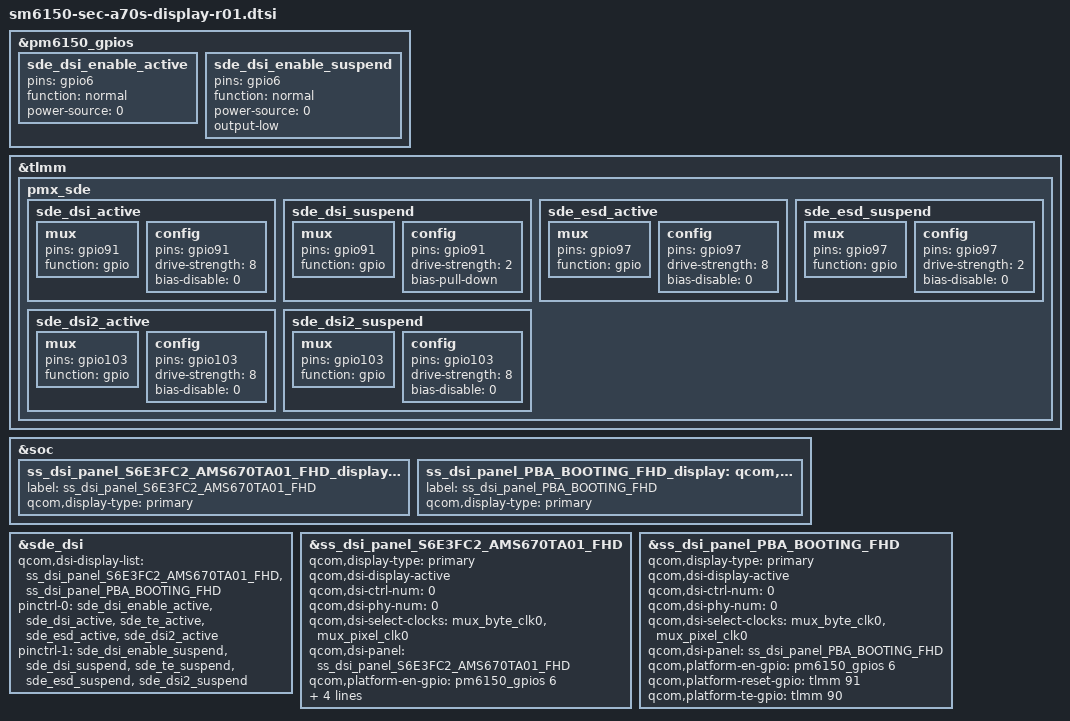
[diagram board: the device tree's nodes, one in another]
/* Copyright (c) 2016-2017, The Linux Foundation. All rights reserved.
 *
 * This program is free software; you can redistribute it and/or modify
 * it under the terms of the GNU General Public License version 2 and
 * only version 2 as published by the Free Software Foundation.
 *
 * This program is distributed in the hope that it will be useful,
 * but WITHOUT ANY WARRANTY; without even the implied warranty of
 * MERCHANTABILITY or FITNESS FOR A PARTICULAR PURPOSE.  See the
 * GNU General Public License for more details.
 */

//#include "../../../../../drivers/gpu/drm/msm/samsung/SELF_DISPLAY/self_display_cmd_FA7_AMS628RF05.dtsi"
#include "../../../../../drivers/gpu/drm/msm/samsung/S6E3FC2_AMS670TA01/dsi_panel_S6E3FC2_AMS670TA01_fhd_octa_cmd.dtsi"
#include "../../../../../drivers/gpu/drm/msm/samsung/S6E3FC2_AMS670TA01/dsi_panel_S6E3FC2_AMS670TA01_fhd_octa_cmd_A70.dtsi"
#include "../../../../../drivers/gpu/drm/msm/samsung/PBA_BOOTING/dsi_panel_PBA_BOOTING_fhd_video.dtsi"


&pm6150_gpios {
	sde_dsi_enable_active: sde_dsi_enable_active {
		pins = "gpio6";
		function = "normal";
		power-source = <0>;
	};

	sde_dsi_enable_suspend: sde_dsi_enable_suspend {
		pins = "gpio6";
		function = "normal";
		power-source = <0>;
		output-low;
	};
};

&tlmm {
	pmx_sde: pmx_sde {
		sde_dsi_active: sde_dsi_active { /*reset gpio*/
			mux {
				pins = "gpio91";
				function = "gpio";
			};

			config {
				pins = "gpio91";
				drive-strength = <8>;   /* 8 mA */
				bias-disable = <0>;   /* no pull */
			};
		};
		sde_dsi_suspend: sde_dsi_suspend {
			mux {
				pins = "gpio91";
				function = "gpio";
			};

			config {
				pins = "gpio91";
				drive-strength = <2>;   /* 2 mA */
				bias-pull-down;         /* PULL DOWN */
			};
		};

		sde_esd_active: sde_esd_active {  /*EL_ON1_DET gpio*/
			mux {
				pins = "gpio97";
				function = "gpio";
			};

			config {
				pins = "gpio97";
				drive-strength = <8>;   /* 8 mA */
				bias-disable = <0>;   /* no pull */
			};
		};
		sde_esd_suspend: sde_esd_suspend {
			mux {
				pins = "gpio97";
				function = "gpio";
			};

			config {
				pins = "gpio97";
				drive-strength = <2>;   /* 2 mA */
				bias-disable = <0>;   /* no pull */
			};
		};

		sde_dsi2_active: sde_dsi2_active { /*OCTA_CON_DET gpio*/
			mux {
				pins = "gpio103";
				function = "gpio";
			};

			config {
				pins = "gpio103";
				drive-strength = <8>;   /* 8 mA */
				bias-disable = <0>;   /* no pull */
			};
		};
		sde_dsi2_suspend: sde_dsi2_suspend {
			mux {
				pins = "gpio103";
				function = "gpio";
			};

			config {
				pins = "gpio103";
				drive-strength = <8>;   /* 8 mA */
				bias-disable = <0>;   /* no pull */
			};
		};
	};
};

&soc {
	/* A70 panel */
	ss_dsi_panel_S6E3FC2_AMS670TA01_FHD_display: qcom,dsi-display@5 {
		label = "ss_dsi_panel_S6E3FC2_AMS670TA01_FHD";
		qcom,display-type = "primary";
	};

	/* PBA */
	ss_dsi_panel_PBA_BOOTING_FHD_display: qcom,dsi-display@6 {
		label = "ss_dsi_panel_PBA_BOOTING_FHD";
		qcom,display-type = "primary";
	};
};

&sde_dsi {
	qcom,dsi-display-list =
		<&ss_dsi_panel_S6E3FC2_AMS670TA01_FHD
		&ss_dsi_panel_PBA_BOOTING_FHD>;

	pinctrl-names = "panel_active", "panel_suspend";
	pinctrl-0 = <&sde_dsi_enable_active &sde_dsi_active &sde_te_active &sde_esd_active &sde_dsi2_active>;
	pinctrl-1 = <&sde_dsi_enable_suspend &sde_dsi_suspend &sde_te_suspend &sde_esd_suspend &sde_dsi2_suspend>;
};

&ss_dsi_panel_S6E3FC2_AMS670TA01_FHD {
	qcom,display-type = "primary";
	qcom,dsi-display-active;

	qcom,dsi-ctrl-num = <0>;
	qcom,dsi-phy-num = <0>;
	qcom,dsi-select-clocks = "mux_byte_clk0", "mux_pixel_clk0";

	qcom,dsi-panel = <&ss_dsi_panel_S6E3FC2_AMS670TA01_FHD>;

	qcom,platform-en-gpio = <&pm6150_gpios 6 0>;
	qcom,platform-reset-gpio = <&tlmm 91 0>;
	qcom,platform-te-gpio = <&tlmm 90 0>;
	samsung,esd-irq-gpio1 = <&tlmm 97 0>;
	samsung,support-optical-fingerprint;
};

&ss_dsi_panel_PBA_BOOTING_FHD {
	qcom,display-type = "primary";
	qcom,dsi-display-active;

	qcom,dsi-ctrl-num = <0>;
	qcom,dsi-phy-num = <0>;
	qcom,dsi-select-clocks = "mux_byte_clk0", "mux_pixel_clk0";

	qcom,dsi-panel = <&ss_dsi_panel_PBA_BOOTING_FHD>;

	qcom,platform-en-gpio = <&pm6150_gpios 6 0>;
	qcom,platform-reset-gpio = <&tlmm 91 0>;
	qcom,platform-te-gpio = <&tlmm 90 0>;
};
